AUTOSAR XML (schema 4-3-0)
package /MICROSAR/BswM_swc
  mode declaration group BswMRteModeDclGroup: initial-mode=BswMRteMode
    mode BswMRteMode
  mode declaration group ESH_Mode: initial-mode=STARTUP
    5 x mode:
      STARTUP
      RUN
      POSTRUN
      WAKEUP
      SHUTDOWN
  mode declaration group ESH_RunRequest: initial-mode=RELEASED
    mode RELEASED
    mode REQUESTED
  data type mapping set BswMMappingSet  # Contains Mapping for ModeDeclarations Groups which are provided by BswM.
    mode-request-type-maps:
      implementation-data-type=BswM_BswMRteModeDclGroup, mode-group=BswMRteModeDclGroup
      implementation-data-type=BswM_ESH_Mode, mode-group=ESH_Mode
      implementation-data-type=BswM_ESH_RunRequest, mode-group=ESH_RunRequest
      implementation-data-type=uint8, mode-group=DarhReportErrorMode
      implementation-data-type=uint8, mode-group=ErrorMemoryLockSignalReceptionMode
      implementation-data-type=uint8, mode-group=StdDiag_SessionModeGroup
      implementation-data-type=NormalCommunicationModeType, mode-group=StdDiag_NormalCommunicationModeGroup
      implementation-data-type=IntegrationSample_EcuRunStateModeRequestType, mode-group=IntegrationSample_EcuRunState
      implementation-data-type=Dlog_LifeCycleRequestType, mode-group=Dlog_LifeCycle
      implementation-data-type=Darh_LifeCycleRequestType, mode-group=Darh_LifeCycle
      implementation-data-type=Omc_LifeCycleRequestType, mode-group=Omc_LifeCycle
      implementation-data-type=SysTime_LifeCycleRequestType, mode-group=SysTime_LifeCycle
      implementation-data-type=StdDiag_LifeCycleRequestType, mode-group=StdDiag_LifeCycle
      implementation-data-type=Dcm_EcuResetType, mode-group=DcmEcuReset
      implementation-data-type=Dcm_DiagnosticSessionControlType, mode-group=DcmDiagnosticSessionControl
      implementation-data-type=Dcm_CommunicationModeType, mode-group=DcmCommunicationControl
      implementation-data-type=Stm_CentralErrorLockType, mode-group=Stm_CentralErrorLockMode
      implementation-data-type=IntegrationSample_SimpleTimerStateType, mode-group=IntegrationSample_SimpleTimerState
      implementation-data-type=Bs_LifeCycleRequestType, mode-group=Bs_LifeCycle
package /MICROSAR/BswM_swc/ComponentTypes
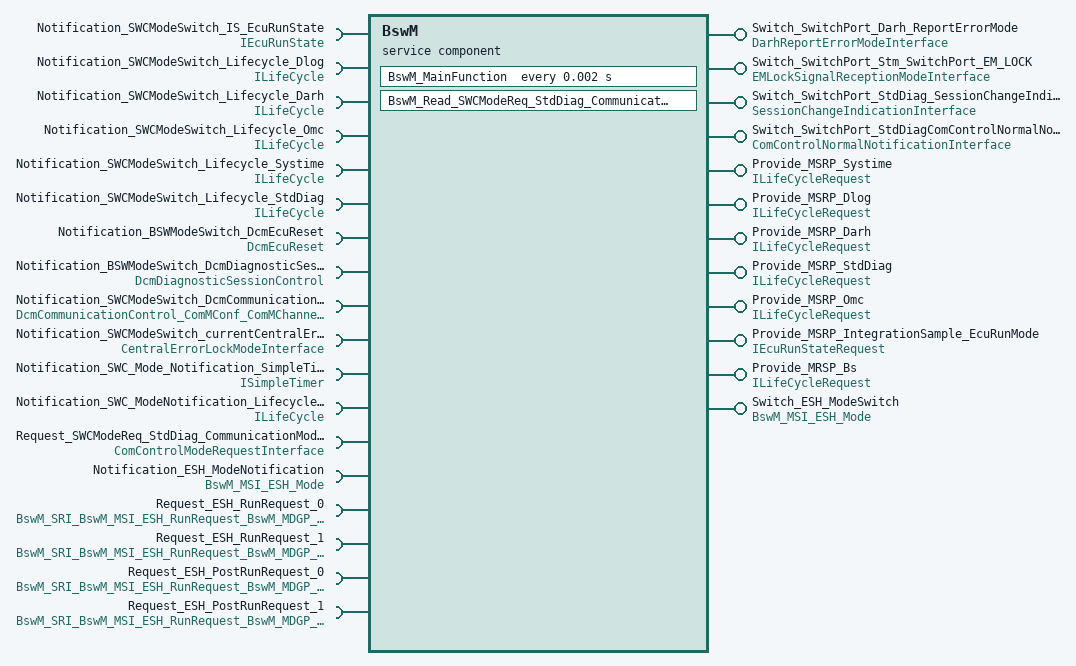
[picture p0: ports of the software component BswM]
  service sw component type BswM: category=SERVICE_COMPONENT
    4 x provide port:
      Switch_SwitchPort_Darh_ReportErrorMode: provided-interface=DarhReportErrorModeInterface
      Switch_SwitchPort_Stm_SwitchPort_EM_LOCK: provided-interface=EMLockSignalReceptionModeInterface
      Switch_SwitchPort_StdDiag_SessionChangeIndication: provided-interface=SessionChangeIndicationInterface
      Switch_SwitchPort_StdDiagComControlNormalNotificationPort: provided-interface=ComControlNormalNotificationInterface
    13 x require port:
      Notification_SWCModeSwitch_IS_EcuRunState: required-interface=IEcuRunState
      Notification_SWCModeSwitch_Lifecycle_Dlog: required-interface=ILifeCycle
      Notification_SWCModeSwitch_Lifecycle_Darh: required-interface=ILifeCycle
      Notification_SWCModeSwitch_Lifecycle_Omc: required-interface=ILifeCycle
      Notification_SWCModeSwitch_Lifecycle_Systime: required-interface=ILifeCycle
      Notification_SWCModeSwitch_Lifecycle_StdDiag: required-interface=ILifeCycle
      Notification_BSWModeSwitch_DcmEcuReset: required-interface=DcmEcuReset
      Notification_BSWModeSwitch_DcmDiagnosticSessionControl: required-interface=DcmDiagnosticSessionControl
      Notification_SWCModeSwitch_DcmCommunicationControl_ComMConf_ComMChannel_BAC4_FlexRay_8e151c3c: required-interface=DcmCommunicationControl_ComMConf_ComMChannel_A_FlexRay_5b5a9ac2
      Notification_SWCModeSwitch_currentCentralErrorLockMode: required-interface=CentralErrorLockModeInterface
      Notification_SWC_Mode_Notification_SimpleTimerMode: required-interface=ISimpleTimer
      Notification_SWC_ModeNotification_Lifecycle_Bs: required-interface=ILifeCycle
      Request_SWCModeReq_StdDiag_CommunicationModeDeclarationGroup: nonqueued-receiver-com-spec{data-element=requestedMode, handle-out-of-range-status=SILENT, init-value=ENABLE_RX_AND_TX_NORMAL}, required-interface=ComControlModeRequestInterface
    8 x provide port:
      Provide_MSRP_Systime: nonqueued-sender-com-spec{data-element=requestMode, init-value=SYSTIME_STOPPED}, provided-interface=ILifeCycleRequest
      Provide_MSRP_Dlog: nonqueued-sender-com-spec{data-element=requestMode, init-value=DLOG_STOPPED}, provided-interface=ILifeCycleRequest
      Provide_MSRP_Darh: nonqueued-sender-com-spec{data-element=requestMode, init-value=DARH_STOPPED}, provided-interface=ILifeCycleRequest
      Provide_MSRP_StdDiag: nonqueued-sender-com-spec{data-element=requestMode, init-value=STDDIAG_STOPPED}, provided-interface=ILifeCycleRequest
      Provide_MSRP_Omc: nonqueued-sender-com-spec{data-element=requestMode, init-value=OMC_STOPPED}, provided-interface=ILifeCycleRequest
      Provide_MSRP_IntegrationSample_EcuRunMode: nonqueued-sender-com-spec{data-element=IntegrationSample_EcuRunStateRequestMode, init-value=IntegrationSample_BSW_START}, provided-interface=IEcuRunStateRequest
      Provide_MRSP_Bs: nonqueued-sender-com-spec{data-element=requestMode, init-value=BS_STOPPED}, provided-interface=ILifeCycleRequest
      Switch_ESH_ModeSwitch: provided-interface=BswM_MSI_ESH_Mode
    5 x require port:
      Notification_ESH_ModeNotification: required-interface=BswM_MSI_ESH_Mode
      Request_ESH_RunRequest_0: nonqueued-receiver-com-spec{data-element=BswM_SRI_BswM_MSI_ESH_RunRequest_BswM_MDGP_ESH_RunRequest/requestedMode, handle-out-of-range-status=SILENT, init-value=RELEASED}, required-interface=BswM_SRI_BswM_MSI_ESH_RunRequest_BswM_MDGP_ESH_RunRequest
      Request_ESH_RunRequest_1: nonqueued-receiver-com-spec{data-element=BswM_SRI_BswM_MSI_ESH_RunRequest_BswM_MDGP_ESH_RunRequest/requestedMode, handle-out-of-range-status=SILENT, init-value=RELEASED}, required-interface=BswM_SRI_BswM_MSI_ESH_RunRequest_BswM_MDGP_ESH_RunRequest
      Request_ESH_PostRunRequest_0: nonqueued-receiver-com-spec{data-element=BswM_SRI_BswM_MSI_ESH_RunRequest_BswM_MDGP_ESH_RunRequest/requestedMode, handle-out-of-range-status=SILENT, init-value=RELEASED}, required-interface=BswM_SRI_BswM_MSI_ESH_RunRequest_BswM_MDGP_ESH_RunRequest
      Request_ESH_PostRunRequest_1: nonqueued-receiver-com-spec{data-element=BswM_SRI_BswM_MSI_ESH_RunRequest_BswM_MDGP_ESH_RunRequest/requestedMode, handle-out-of-range-status=SILENT, init-value=RELEASED}, required-interface=BswM_SRI_BswM_MSI_ESH_RunRequest_BswM_MDGP_ESH_RunRequest
    behavior BswMInternalBehavior: data-type-mapping=BswMMappingSet, handle-termination-and-restart=NO-SUPPORT, included-data-type-set=data-type=[BswM_BswMRteModeDclGroup, BswM_ESH_Mode, BswM_ESH_RunRequest]
      timing event Timer_BswM_MainFunction: start-on-event=BswM_MainFunction, period=0.002
      data received event DataReceivedEvent_BswM_Read_SWCModeReq_StdDiag_CommunicationModeDeclarationGroup_Request_SWCModeReq_StdDiag_Communicati_699d3eef: start-on-event=BswM_Read_SWCModeReq_StdDiag_CommunicationModeDeclarationGroup, data=Request_SWCModeReq_StdDiag_CommunicationModeDeclarationGroup.requestedMode
      port-api-options:
        enable-take-address=true, indirect-api=false, port=Switch_SwitchPort_Darh_ReportErrorMode
        enable-take-address=true, indirect-api=false, port=Switch_SwitchPort_Stm_SwitchPort_EM_LOCK
        enable-take-address=true, indirect-api=false, port=Switch_SwitchPort_StdDiag_SessionChangeIndication
        enable-take-address=true, indirect-api=false, port=Switch_SwitchPort_StdDiagComControlNormalNotificationPort
        enable-take-address=true, indirect-api=false, port=Switch_ESH_ModeSwitch
        enable-take-address=true, indirect-api=false, port=Notification_SWCModeSwitch_IS_EcuRunState
        enable-take-address=true, indirect-api=false, port=Notification_SWCModeSwitch_Lifecycle_Dlog
        enable-take-address=true, indirect-api=false, port=Notification_SWCModeSwitch_Lifecycle_Darh
        enable-take-address=true, indirect-api=false, port=Notification_SWCModeSwitch_Lifecycle_Omc
        enable-take-address=true, indirect-api=false, port=Notification_SWCModeSwitch_Lifecycle_Systime
        enable-take-address=true, indirect-api=false, port=Notification_SWCModeSwitch_Lifecycle_StdDiag
        enable-take-address=true, indirect-api=false, port=Notification_BSWModeSwitch_DcmEcuReset
        enable-take-address=true, indirect-api=false, port=Notification_BSWModeSwitch_DcmDiagnosticSessionControl
        enable-take-address=true, indirect-api=false, port=Notification_SWCModeSwitch_DcmCommunicationControl_ComMConf_ComMChannel_BAC4_FlexRay_8e151c3c
        enable-take-address=true, indirect-api=false, port=Notification_SWCModeSwitch_currentCentralErrorLockMode
        enable-take-address=true, indirect-api=false, port=Notification_SWC_Mode_Notification_SimpleTimerMode
        enable-take-address=true, indirect-api=false, port=Notification_SWC_ModeNotification_Lifecycle_Bs
        enable-take-address=true, indirect-api=false, port=Notification_ESH_ModeNotification
        enable-take-address=true, indirect-api=false, port=Request_SWCModeReq_StdDiag_CommunicationModeDeclarationGroup
        enable-take-address=true, indirect-api=false, port=Request_ESH_RunRequest_0
        enable-take-address=true, indirect-api=false, port=Request_ESH_RunRequest_1
        enable-take-address=true, indirect-api=false, port=Request_ESH_PostRunRequest_0
        enable-take-address=true, indirect-api=false, port=Request_ESH_PostRunRequest_1
        enable-take-address=true, indirect-api=false, port=Provide_MSRP_Systime
        enable-take-address=true, indirect-api=false, port=Provide_MSRP_Dlog
        enable-take-address=true, indirect-api=false, port=Provide_MSRP_Darh
        enable-take-address=true, indirect-api=false, port=Provide_MSRP_StdDiag
        enable-take-address=true, indirect-api=false, port=Provide_MSRP_Omc
        enable-take-address=true, indirect-api=false, port=Provide_MSRP_IntegrationSample_EcuRunMode
        enable-take-address=true, indirect-api=false, port=Provide_MRSP_Bs
      runnable BswM_MainFunction
        data-receive-point-by-arguments:
          4 x access:
            DataReceivePointBswM_MainFunction_Request_ESH_RunRequest_0_requestedMode: accessed-variable=Request_ESH_RunRequest_0.requestedMode
            DataReceivePointBswM_MainFunction_Request_ESH_RunRequest_1_requestedMode: accessed-variable=Request_ESH_RunRequest_1.requestedMode
            DataReceivePointBswM_MainFunction_Request_ESH_PostRunRequest_0_requestedMode: accessed-variable=Request_ESH_PostRunRequest_0.requestedMode
            DataReceivePointBswM_MainFunction_Request_ESH_PostRunRequest_1_requestedMode: accessed-variable=Request_ESH_PostRunRequest_1.requestedMode
        data-send-points:
          7 x access:
            DataSendPointBswM_MainFunction_Provide_MSRP_Systime_requestMode: accessed-variable=Provide_MSRP_Systime.requestMode
            DataSendPointBswM_MainFunction_Provide_MSRP_Dlog_requestMode: accessed-variable=Provide_MSRP_Dlog.requestMode
            DataSendPointBswM_MainFunction_Provide_MSRP_Darh_requestMode: accessed-variable=Provide_MSRP_Darh.requestMode
            DataSendPointBswM_MainFunction_Provide_MSRP_StdDiag_requestMode: accessed-variable=Provide_MSRP_StdDiag.requestMode
            DataSendPointBswM_MainFunction_Provide_MSRP_Omc_requestMode: accessed-variable=Provide_MSRP_Omc.requestMode
            DataSendPointBswM_MainFunction_Provide_MSRP_IntegrationSample_EcuRunMode_IntegrationSample_EcuRunStateRequestMode: accessed-variable=Provide_MSRP_IntegrationSample_EcuRunMode.IntegrationSample_EcuRunStateRequestMode
            DataSendPointBswM_MainFunction_Provide_MRSP_Bs_requestMode: accessed-variable=Provide_MRSP_Bs.requestMode
        mode-access-points:
          Notification_SWCModeSwitch_IS_EcuRunState.EcuRunStateMode
          Notification_SWCModeSwitch_Lifecycle_Dlog.Mode
          Notification_SWCModeSwitch_Lifecycle_Darh.Mode
          Notification_SWCModeSwitch_Lifecycle_Omc.Mode
          Notification_SWCModeSwitch_Lifecycle_Systime.Mode
          Notification_SWCModeSwitch_Lifecycle_StdDiag.Mode
          Notification_BSWModeSwitch_DcmEcuReset.DcmEcuReset
          Notification_BSWModeSwitch_DcmDiagnosticSessionControl.DcmDiagnosticSessionControl
          Notification_SWCModeSwitch_DcmCommunicationControl_ComMConf_ComMChannel_BAC4_FlexRay_8e151c3c.DcmCommunicationControl_ComMConf_ComMChannel_A_FlexRay_5b5a9ac2
          Notification_SWCModeSwitch_currentCentralErrorLockMode.currentCentralErrorLockMode
          Notification_SWC_Mode_Notification_SimpleTimerMode.SimpleTimerMode
          Notification_SWC_ModeNotification_Lifecycle_Bs.Mode
          Notification_ESH_ModeNotification.BswM_MDGP_ESH_Mode
        5 x mode switch point:
          ModeSwitchPointBswM_MainFunction_Switch_SwitchPort_Darh_ReportErrorMode_DarhReportErrorMode: mode-group=Switch_SwitchPort_Darh_ReportErrorMode.DarhReportErrorMode
          ModeSwitchPointBswM_MainFunction_Switch_SwitchPort_Stm_SwitchPort_EM_LOCK_currentEMLockSignalReceptionMode: mode-group=Switch_SwitchPort_Stm_SwitchPort_EM_LOCK.currentEMLockSignalReceptionMode
          ModeSwitchPointBswM_MainFunction_Switch_SwitchPort_StdDiag_SessionChangeIndication_SessionModeDeclarationGroup: mode-group=Switch_SwitchPort_StdDiag_SessionChangeIndication.SessionModeDeclarationGroup
          ModeSwitchPointBswM_MainFunction_Switch_SwitchPort_StdDiagComControlNormalNotificationPort_CommunicationModeDeclarationGroup: mode-group=Switch_SwitchPort_StdDiagComControlNormalNotificationPort.CommunicationModeDeclarationGroup
          ModeSwitchPointBswM_MainFunction_Switch_ESH_ModeSwitch_BswM_MDGP_ESH_Mode: mode-group=Switch_ESH_ModeSwitch.BswM_MDGP_ESH_Mode
      runnable BswM_Read_SWCModeReq_StdDiag_CommunicationModeDeclarationGroup: can-be-invoked-concurrently=true
        data-receive-point-by-arguments:
          access DataReceivePointBswM_Read_SWCModeReq_StdDiag_CommunicationModeDeclarationGroup_Request_SWCModeReq_StdDiag_Communication_379ffe94: accessed-variable=Request_SWCModeReq_StdDiag_CommunicationModeDeclarationGroup.requestedMode
  swc implementation BswMImplementation: programming-language=C, behavior=BswMInternalBehavior
package /MICROSAR/BswM_swc/DataTypes
  impl type BswM_BswMRteModeDclGroup: compu {0=BswMRteMode}, implementation-data-type=uint8  # Unique value for each user
  impl type BswM_ESH_Mode: compu {0=STARTUP, 1=RUN, 2=POSTRUN, 3=WAKEUP, 4=SHUTDOWN}, implementation-data-type=uint8  # Unique value for each user
  impl type BswM_ESH_RunRequest: compu {0=RELEASED, 1=REQUESTED}, implementation-data-type=uint8  # Unique value for each user
package /MICROSAR/BswM_swc/Interfaces
  mode switch interface BswM_MSI_BswMRteModeDclGroup: is-service=true, service-kind=BASIC-SOFTWARE-MODE-MANAGER
    mode group BswM_MDGP_BswMRteModeDclGroup: type=BswMRteModeDclGroup
  sender receiver interface BswM_SRI_BswM_MSI_BswMRteModeDclGroup_BswM_MDGP_BswMRteModeDclGroup: is-service=true, service-kind=BASIC-SOFTWARE-MODE-MANAGER
    data requestedMode: type=BswM_BswMRteModeDclGroup
  mode switch interface BswM_MSI_ESH_Mode: is-service=true, service-kind=BASIC-SOFTWARE-MODE-MANAGER
    mode group BswM_MDGP_ESH_Mode: type=ESH_Mode
  sender receiver interface BswM_SRI_BswM_MSI_ESH_Mode_BswM_MDGP_ESH_Mode: is-service=true, service-kind=BASIC-SOFTWARE-MODE-MANAGER
    data requestedMode: type=BswM_ESH_Mode
  mode switch interface BswM_MSI_ESH_RunRequest: is-service=true, service-kind=BASIC-SOFTWARE-MODE-MANAGER
    mode group BswM_MDGP_ESH_RunRequest: type=ESH_RunRequest
  sender receiver interface BswM_SRI_BswM_MSI_ESH_RunRequest_BswM_MDGP_ESH_RunRequest: is-service=true, service-kind=BASIC-SOFTWARE-MODE-MANAGER
    data requestedMode: type=BswM_ESH_RunRequest
